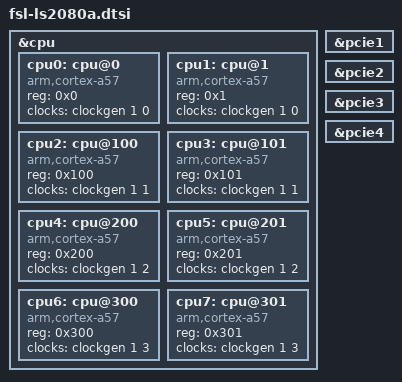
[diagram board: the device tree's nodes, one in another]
/*
 * Device Tree Include file for Freescale Layerscape-2080A family SoC.
 *
 * Copyright (C) 2014-2016, Freescale Semiconductor
 *
 * Abhimanyu Saini <abhimanyu.saini@nxp.com>
 * Bhupesh Sharma <bhupesh.sharma@freescale.com>
 * Harninder Rai <harninder.rai@freescale.com>
 *
 * This file is licensed under the terms of the GNU General Public
 * License version 2.  This program is licensed "as is" without any
 * warranty of any kind, whether express or implied.
 */

/memreserve/ 0x80000000 0x00010000;

#include "fsl-ls208xa.dtsi"


&cpu {
	cpu0: cpu@0 {
		device_type = "cpu";
		compatible = "arm,cortex-a57";
		reg = <0x0>;
		clocks = <&clockgen 1 0>;
		#cooling-cells = <2>;
	};

	cpu1: cpu@1 {
		device_type = "cpu";
		compatible = "arm,cortex-a57";
		reg = <0x1>;
		clocks = <&clockgen 1 0>;
	};

	cpu2: cpu@100 {
		device_type = "cpu";
		compatible = "arm,cortex-a57";
		reg = <0x100>;
		clocks = <&clockgen 1 1>;
		#cooling-cells = <2>;
	};

	cpu3: cpu@101 {
		device_type = "cpu";
		compatible = "arm,cortex-a57";
		reg = <0x101>;
		clocks = <&clockgen 1 1>;
	};

	cpu4: cpu@200 {
		device_type = "cpu";
		compatible = "arm,cortex-a57";
		reg = <0x200>;
		clocks = <&clockgen 1 2>;
		#cooling-cells = <2>;
	};

	cpu5: cpu@201 {
		device_type = "cpu";
		compatible = "arm,cortex-a57";
		reg = <0x201>;
		clocks = <&clockgen 1 2>;
	};

	cpu6: cpu@300 {
		device_type = "cpu";
		compatible = "arm,cortex-a57";
		reg = <0x300>;
		clocks = <&clockgen 1 3>;
		#cooling-cells = <2>;
	};

	cpu7: cpu@301 {
		device_type = "cpu";
		compatible = "arm,cortex-a57";
		reg = <0x301>;
		clocks = <&clockgen 1 3>;
	};
};

&pcie1 {
	ranges = <0x81000000 0x0 0x00000000 0x10 0x00010000 0x0 0x00010000   /* downstream I/O */
		  0x82000000 0x0 0x40000000 0x10 0x40000000 0x0 0x40000000>; /* non-prefetchable memory */
};

&pcie2 {
	ranges = <0x81000000 0x0 0x00000000 0x12 0x00010000 0x0 0x00010000   /* downstream I/O */
		  0x82000000 0x0 0x40000000 0x12 0x40000000 0x0 0x40000000>; /* non-prefetchable memory */
};

&pcie3 {
	ranges = <0x81000000 0x0 0x00000000 0x14 0x00010000 0x0 0x00010000   /* downstream I/O */
		  0x82000000 0x0 0x40000000 0x14 0x40000000 0x0 0x40000000>; /* non-prefetchable memory */
};
&pcie4 {
	ranges = <0x81000000 0x0 0x00000000 0x16 0x00010000 0x0 0x00010000   /* downstream I/O */
		  0x82000000 0x0 0x40000000 0x16 0x40000000 0x0 0x40000000>; /* non-prefetchable memory */
};
